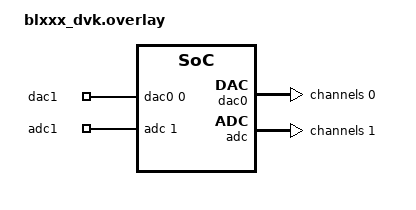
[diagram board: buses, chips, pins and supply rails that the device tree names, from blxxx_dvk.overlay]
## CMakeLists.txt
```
# SPDX-License-Identifier: Apache-2.0

cmake_minimum_required(VERSION 3.28.0)

find_package(Zephyr REQUIRED HINTS $ENV{ZEPHYR_BASE})
project(dac_loopback)

FILE(GLOB app_sources src/*.c)
target_sources(app PRIVATE ${app_sources})
```

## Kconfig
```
# Copyright (c) 2025 Renesas Electronics Corporation
# SPDX-License-Identifier: Apache-2.0

mainmenu "DAC Loopback test"

source "Kconfig.zephyr"

config DAC_BUFFER_NOT_SUPPORT
	bool "DAC on board/SoC does not support output buffer mode"
	help
	  If this config is turned on, the test will run with no output buffer enabled
```

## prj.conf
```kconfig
CONFIG_ZTEST=y

CONFIG_DAC=y
CONFIG_ADC=y
```

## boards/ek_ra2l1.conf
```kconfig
# Copyright (c) 2025 Renesas Electronics Corporation
# SPDX-License-Identifier: Apache-2.0

CONFIG_DAC_BUFFER_NOT_SUPPORT=y
```

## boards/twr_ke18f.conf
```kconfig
CONFIG_DAC_MCUX_DAC32_TESTOUT=y
```

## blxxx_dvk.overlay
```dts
/*
 * Copyright 2021 Laird Connectivity
 *
 * SPDX-License-Identifier: Apache-2.0
 */

/ {
	zephyr,user {
		io-channels = <&dac0 0 &adc 1>;
		io-channel-names = "dac1", "adc1";
	};
};

&dac0 {

	#address-cells = <1>;
	#size-cells = <0>;
	status = "okay";

	channel@0 {
		reg = <0>;
		zephyr,resolution = <12>;
	};
};

&adc {

	#address-cells = <1>;
	#size-cells = <0>;
	status = "okay";

	channel@1 {
		reg = <1>;
		zephyr,gain = "ADC_GAIN_1_4";
		zephyr,reference = "ADC_REF_VDD_1_4";
		zephyr,resolution = <12>;
		zephyr,acquisition-time = <ADC_ACQ_TIME_DEFAULT>;
		zephyr,input-positive = <NRF_SAADC_AIN1>;
	};
};
```

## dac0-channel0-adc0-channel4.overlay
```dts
/*
 * Copyright (c) 2026 Texas Instruments Incorporated
 *
 * SPDX-License-Identifier: Apache-2.0
 */

/ {
	zephyr,user {
		io-channels = <&dac0 0 &adc0 4>;
		io-channel-names = "dac1", "adc1";
	};
};
```

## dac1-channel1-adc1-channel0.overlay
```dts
/*
 * Copyright (c) 2026 Analog Devices, Inc
 *
 * SPDX-License-Identifier: Apache-2.0
 */

/ {
	zephyr,user {
		io-channels = <&dac1 1 &adc1 0>;
		io-channel-names = "dac1", "adc1";
	};
};

&dac1 {
	status = "okay";

	#address-cells = <1>;
	#size-cells = <0>;

	channel@1 {
		reg = <1>;
		zephyr,resolution = <12>;
	};
};

&adc1 {
	status = "okay";

	#address-cells = <1>;
	#size-cells = <0>;

	channel@0 {
		reg = <0>;
		zephyr,gain = "ADC_GAIN_1";
		zephyr,reference = "ADC_REF_INTERNAL";
		zephyr,resolution = <12>;
		zephyr,acquisition-time = <ADC_ACQ_TIME_MAX>;
	};
};
```

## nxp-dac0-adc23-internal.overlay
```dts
/*
 * Copyright 2020 Henrik Brix Andersen <henrik@brixandersen.dk>
 * Copyright 2026 Analog Devices, Inc
 *
 * SPDX-License-Identifier: Apache-2.0
 */

/* DAC0 output is internally available on ADC0_SE23 */

/ {
	zephyr,user {
		io-channels = <&dac0 0 &adc0 23>;
		io-channel-names = "dac1", "adc1";
	};
};

&dac0 {

	#address-cells = <1>;
	#size-cells = <0>;
	status = "okay";

	channel@0 {
		reg = <0>;
		zephyr,resolution = <12>;
	};
};

&adc0 {

	#address-cells = <1>;
	#size-cells = <0>;
	status = "okay";

	channel@23 {
		reg = <23>;
		zephyr,gain = "ADC_GAIN_1";
		zephyr,reference = "ADC_REF_INTERNAL";
		zephyr,resolution = <12>;
		zephyr,acquisition-time = <ADC_ACQ_TIME_DEFAULT>;
	};
};
```

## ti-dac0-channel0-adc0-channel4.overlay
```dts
/*
 * Copyright (c) 2026 Texas Instruments Incorporated
 *
 * SPDX-License-Identifier: Apache-2.0
 */

#include <dt-bindings/adc/adc.h>

/ {
	zephyr,user {
		io-channels = <&dac0 0 &adc0 4>;
		io-channel-names = "dac1", "adc1";
	};
};

&dac0 {
	#address-cells = <1>;
	#size-cells = <0>;

	channel@0 {
		reg = <0>;
		zephyr,resolution = <12>;
		zephyr,buffered;
	};
};

&adc0 {
	clocks = <&ckm MSPM0_CLOCK_ULPCLK>;
	max-result-reg = <12>;
	pinctrl-0 = <&analog_pb25>;
	pinctrl-names = "default";
	#address-cells = <1>;
	#size-cells = <0>;
	ti,clk-divider = <1>;
	ti,clk-range = <6>;
	status = "okay";

	channel@4 {
		reg = <4>;
		zephyr,gain = "ADC_GAIN_1";
		zephyr,reference = "ADC_REF_VDD_1";
		zephyr,acquisition-time = <ADC_ACQ_TIME_DEFAULT>;
		zephyr,resolution = <12>;
	};
};
```

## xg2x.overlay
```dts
/*
 * Copyright (c) 2025 Silicon Laboratories Inc.
 *
 * SPDX-License-Identifier: Apache-2.0
 */

#include <zephyr/dt-bindings/adc/silabs-adc.h>
#include <zephyr/dt-bindings/dac/silabs-vdac.h>

/ {
	zephyr,user {
		io-channels = <&vdac0 0 &adc0 0>;
		io-channel-names = "dac1", "adc1";
	};
};

&adc0 {
	#address-cells = <1>;
	#size-cells = <0>;
	status = "okay";

	channel@0 {
		reg = <0>;
		zephyr,gain = "ADC_GAIN_1";
		zephyr,reference = "ADC_REF_VDD_1";
		zephyr,acquisition-time = <ADC_ACQ_TIME_DEFAULT>;
		zephyr,resolution = <12>;
		zephyr,input-positive = <IADC_INPUT_DAC0>;
	};
};

&vdac0 {
	voltage-reference = "AVDD";
	status = "okay";

	channel@0 {
		reg = <0>;
		aux-output = <VDAC_OUTPUT_AUX>;
		zephyr,resolution = <12>;
	};
};
```

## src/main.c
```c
/*
 * Copyright (c) 2020 Libre Solar Technologies GmbH
 *
 * SPDX-License-Identifier: Apache-2.0
 */

/**
 * @addtogroup t_driver_dac
 * @{
 * @defgroup t_dac_loopback test_dac_loopback
 * @}
 */

#include <zephyr/kernel.h>
#include <zephyr/ztest.h>

extern void test_dac_loopback(void);

void test_main(void)
{
	ztest_test_suite(dac_loopback_test,
			 ztest_unit_test(test_dac_loopback));
	ztest_run_test_suite(dac_loopback_test);
}
```

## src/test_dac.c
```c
/*
 * Copyright (c) 2020 Libre Solar Technologies GmbH
 *
 * SPDX-License-Identifier: Apache-2.0
 */

/*
 * @addtogroup test_dac_loopback
 * @{
 * @defgroup t_dac_basic_loopback test_dac_loopback
 * @brief TestPurpose: read back DAC driver output with ADC
 * @}
 */

#include <zephyr/drivers/dac.h>
#include <zephyr/drivers/adc.h>
#include <zephyr/kernel.h>
#include <zephyr/ztest.h>

/*
 * We need to define an ADC channel to read back the output generated by the
 * ADC. The two pins need to be connected with a jumper in order to pass the
 * test in actual hardware.
 *
 * ADC and DAC need to use the same reference voltage, as the test sampling
 * point is at half of the full scale voltage.
 */

static const struct dac_dt_spec dac_spec =
	DAC_DT_SPEC_GET_BY_NAME_OR(DT_PATH(zephyr_user), dac1, {0});
static const struct adc_dt_spec adc_spec =
	ADC_DT_SPEC_GET_BY_NAME_OR(DT_PATH(zephyr_user), adc1, {0});

static int init_dac(void)
{
	int ret;

	if (!dac_spec.dev) {
		return -ENODEV;
	}

	zassert_true(dac_is_ready_dt(&dac_spec), "DAC device is not ready");

	ret = dac_channel_setup_dt(&dac_spec);
	zassert_ok(ret, "Setting up of the first channel failed with code %d", ret);
	return 0;
}

/* ADC necessary to read back the value from DAC */
static int init_adc(void)
{
	int ret;

	if (!adc_spec.dev) {
		return -ENODEV;
	}

	zassert_true(adc_is_ready_dt(&adc_spec), "ADC device is not ready");

	ret = adc_channel_setup_dt(&adc_spec);
	zassert_ok(ret, "Setting up of the ADC channel failed with code %d", ret);
	return 0;
}

/*
 * test_dac_loopback
 */
static int test_task_loopback(void)
{
	int ret;

	ret = init_adc();
	if (ret == -ENODEV) {
		TC_PRINT("No io-channel named 'adc1' available for testing.\n");
		ztest_test_skip();
		return TC_SKIP;
	}

	ret = init_dac();

	if (ret == -ENODEV) {
		TC_PRINT("No io-channel named 'dac1' available for testing.\n");
		ztest_test_skip();
		return TC_SKIP;
	}

	/* write a value of half the full scale resolution */
	ret = dac_write_value_dt(&dac_spec, (1U << dac_spec.channel_cfg.resolution) / 2);
	zassert_ok(ret, "dac_write_value() failed with code %d", ret);

	/* wait to let DAC output settle */
	k_sleep(K_MSEC(10));

	static int32_t m_sample_buffer[1];
	static struct adc_sequence sequence = {
		.buffer      = m_sample_buffer,
		.buffer_size = sizeof(m_sample_buffer),
	};

	adc_sequence_init_dt(&adc_spec, &sequence);

	ret = adc_read_dt(&adc_spec, &sequence);
	zassert_ok(ret, "adc_read() failed with code %d", ret);
	zassert_within(m_sample_buffer[0],
		(1U << adc_spec.resolution) / 2, 32,
		"Value %d read from ADC does not match expected range.",
		m_sample_buffer[0]);

	return TC_PASS;
}

ZTEST(dac_loopback, test_dac_loopback)
{
	zassert_true(test_task_loopback() == TC_PASS);
}

ZTEST_SUITE(dac_loopback, NULL, NULL, NULL, NULL, NULL);
```
